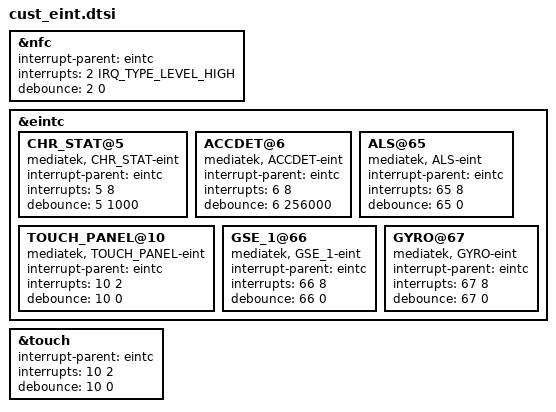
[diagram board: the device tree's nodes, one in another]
/*
 * Generated by MTK SP Drv_CodeGen Version 03.13.6  for MT6735. Copyright MediaTek Inc. (C) 2013.
 * Thu May 28 10:14:14 2015
 * Do Not Modify the File.
 */

/*************************
 * EINT DTSI File
*************************/

#include <dt-bindings/interrupt-controller/irq.h>
#include <dt-bindings/interrupt-controller/arm-gic.h>

&nfc {
	interrupt-parent = <&eintc>;
	interrupts = <2 IRQ_TYPE_LEVEL_HIGH>;
	debounce = <2 0>;
	status = "okay";
};

&eintc {
	CHR_STAT@5 {
        compatible = "mediatek, CHR_STAT-eint";
        interrupt-parent = <&eintc>;
        interrupts = <5 8>;
        debounce = <5 1000>;
    };

	ACCDET@6 {
		compatible = "mediatek, ACCDET-eint";
		interrupt-parent = <&eintc>;
		interrupts = <6 8>;
		debounce = <6 256000>;
	};

	TOUCH_PANEL@10 {
		compatible = "mediatek, TOUCH_PANEL-eint";
		interrupt-parent = <&eintc>;
		interrupts = <10 2>;
		debounce = <10 0>;
	};

	ALS@65 {
		compatible = "mediatek, ALS-eint";
		interrupt-parent = <&eintc>;
		interrupts = <65 8>;
		debounce = <65 0>;
	};

	GSE_1@66 {
		compatible = "mediatek, GSE_1-eint";
		interrupt-parent = <&eintc>;
		interrupts = <66 8>;
		debounce = <66 0>;
	};

	GYRO@67 {
		compatible = "mediatek, GYRO-eint";
		interrupt-parent = <&eintc>;
		interrupts = <67 8>;
		debounce = <67 0>;
	};

};
&touch {
	interrupt-parent = <&eintc>;
	interrupts = <10 2>;
	debounce = <10 0>;
};
